VERSION ""

NS_ :

BS_:

BU_: ACC_ECU

BO_ 256 Throttle: 8 ACC_ECU
 SG_ ThrottlePosition : 0|16@1+ (0.01,0) [0|100] "%" Vector__XXX
 SG_ ThrottleStatus : 16|8@1+ (1,0) [0|3] "" Vector__XXX

BO_ 257 VehicleSpeed: 8 ACC_ECU
 SG_ Speed : 0|32@1+ (0.01,0) [0|300] "km/h" Vector__XXX
 SG_ SpeedValid : 32|8@1+ (1,0) [0|1] "" Vector__XXX

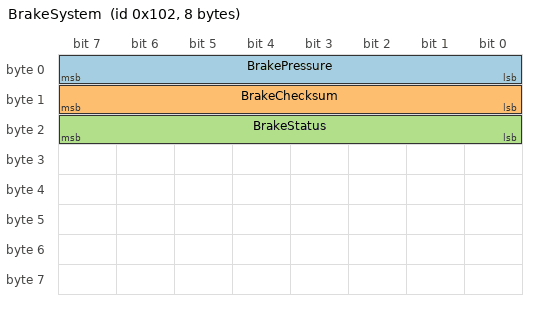
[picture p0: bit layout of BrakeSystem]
BO_ 258 BrakeSystem: 8 ACC_ECU
 SG_ BrakePressure : 0|8@1+ (1,0) [0|255] "bar" Vector__XXX
 SG_ BrakeChecksum : 8|8@1+ (1,0) [0|255] "" Vector__XXX
 SG_ BrakeStatus : 16|8@1+ (1,0) [0|3] "" Vector__XXX

CM_ BO_ 256 "Throttle position message from ACC ECU - 10ms cycle";
CM_ BO_ 257 "Vehicle speed message from ACC ECU - 20ms cycle";
CM_ BO_ 258 "Brake system message from ACC ECU - 10ms cycle";

CM_ SG_ 256 ThrottlePosition "Throttle pedal position 0-100%";
CM_ SG_ 256 ThrottleStatus "0=Init, 1=Normal, 2=Error, 3=NotAvailable";
CM_ SG_ 257 Speed "Vehicle speed in km/h";
CM_ SG_ 257 SpeedValid "1=Valid, 0=Invalid";
CM_ SG_ 258 BrakePressure "Brake pressure 0-255 bar";
CM_ SG_ 258 BrakeChecksum "XOR checksum of data bytes";
CM_ SG_ 258 BrakeStatus "0=Released, 1=Applied, 2=Emergency, 3=Error";

BA_DEF_ BO_ "GenMsgCycleTime" INT 0 10000;
BA_DEF_DEF_ "GenMsgCycleTime" 100;

BA_ "GenMsgCycleTime" BO_ 256 10;
BA_ "GenMsgCycleTime" BO_ 257 20;
BA_ "GenMsgCycleTime" BO_ 258 10;

VAL_ 256 ThrottleStatus 0 "Init" 1 "Normal" 2 "Error" 3 "NotAvailable";
VAL_ 257 SpeedValid 0 "Invalid" 1 "Valid";
VAL_ 258 BrakeStatus 0 "Released" 1 "Applied" 2 "Emergency" 3 "Error";
